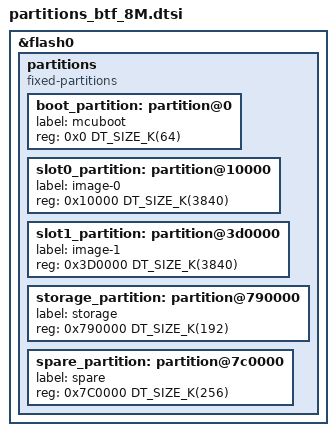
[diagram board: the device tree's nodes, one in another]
/*
 * SPDX-License-Identifier: Apache-2.0
 *
 * 8MB layout for the ESP32-C6-WROOM-1-N8 rework of the BTF board.
 *
 * Derived from Zephyr's partitions_0x0_default_8M.dtsi (the C6 boots from
 * flash offset 0x0, unlike the classic ESP32's 0x1000) with the lpcore,
 * scratch, coredump AND sys partitions deleted: we never enable the LP
 * core, MCUboot runs overwrite-only (no scratch), and the stock "sys"
 * partition's only consumer in the tree is the virtual-eFuse test mode
 * (ESP32_EFUSE_VIRTUAL_KEEP_IN_FLASH), which we don't use. Slots must be
 * 64K-aligned for the flash MMU; slot0 starts right after MCUboot.
 */

&flash0 {
	partitions {
		compatible = "fixed-partitions";
		#address-cells = <1>;
		#size-cells = <1>;

		boot_partition: partition@0 {
			label = "mcuboot";
			reg = <0x0 DT_SIZE_K(64)>;
		};

		slot0_partition: partition@10000 {
			label = "image-0";
			reg = <0x10000 DT_SIZE_K(3840)>;
		};

		slot1_partition: partition@3d0000 {
			label = "image-1";
			reg = <0x3D0000 DT_SIZE_K(3840)>;
		};

		/* Zephyr settings/NVS: Matter fabrics + KVS, WiFi credentials,
		 * and the chip-fct provisioning keys (pairing code).
		 */
		storage_partition: partition@790000 {
			label = "storage";
			reg = <0x790000 DT_SIZE_K(192)>;
		};

		/* Future factory-data partition or coredump space. */
		spare_partition: partition@7c0000 {
			label = "spare";
			reg = <0x7C0000 DT_SIZE_K(256)>;
		};
	};
};

/* Remaining flash size is 0kB
 * Last used address is 0x7FFFFF
 */
